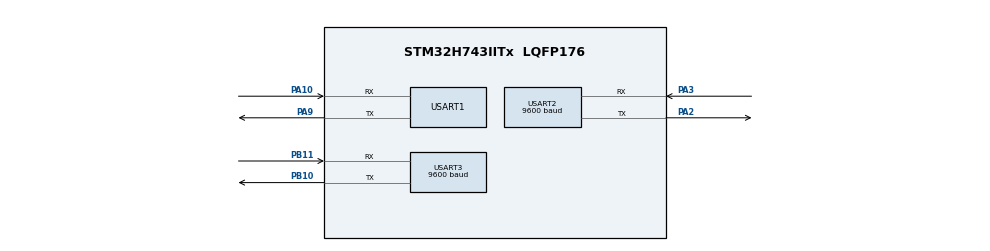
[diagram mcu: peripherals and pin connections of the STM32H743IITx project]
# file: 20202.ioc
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CORTEX_M7.CPU_DCache=Enabled
CORTEX_M7.CPU_ICache=Enabled
CORTEX_M7.default_mode_Activation=1
Mcu.Family=STM32H7
Mcu.Name=STM32H743IITx
Mcu.Package=LQFP176
NVIC.PriorityGroup=NVIC_PRIORITYGROUP_4
PA10.Mode=Asynchronous
PA10.Signal=USART1_RX
PA2.Mode=Asynchronous
PA2.Signal=USART2_TX
PA3.Mode=Asynchronous
PA3.Signal=USART2_RX
PA9.Mode=Asynchronous
PA9.Signal=USART1_TX
PB10.Mode=Asynchronous
PB10.Signal=USART3_TX
PB11.Mode=Asynchronous
PB11.Signal=USART3_RX
PC14-OSC32_IN\ (OSC32_IN).Mode=LSE-External-Oscillator
PC14-OSC32_IN\ (OSC32_IN).Signal=RCC_OSC32_IN
PC15-OSC32_OUT\ (OSC32_OUT).Mode=LSE-External-Oscillator
PC15-OSC32_OUT\ (OSC32_OUT).Signal=RCC_OSC32_OUT
PH0-OSC_IN\ (PH0).Mode=HSE-External-Oscillator
PH0-OSC_IN\ (PH0).Signal=RCC_OSC_IN
PH1-OSC_OUT\ (PH1).Mode=HSE-External-Oscillator
PH1-OSC_OUT\ (PH1).Signal=RCC_OSC_OUT
ProjectManager.HeapSize=0x200
ProjectManager.StackSize=0x400
ProjectManager.TargetToolchain=MDK-ARM V5.32
RCC.ADCFreq_Value=129000000
RCC.APB1Freq_Value=32000000
RCC.APB2Freq_Value=32000000
RCC.APB3Freq_Value=64000000
RCC.APB4Freq_Value=64000000
RCC.CortexFreq_Value=64000000
RCC.D2PPRE1=RCC_APB1_DIV2
RCC.D2PPRE2=RCC_APB2_DIV2
RCC.HCLKFreq_Value=64000000
RCC.SYSCLKFreq_VALUE=64000000
RCC.USBFreq_Value=129000000
USART1.VirtualMode-Asynchronous=VM_ASYNC
USART2.BaudRate=9600
USART2.VirtualMode-Asynchronous=VM_ASYNC
USART3.BaudRate=9600
USART3.VirtualMode-Asynchronous=VM_ASYNC
board=custom

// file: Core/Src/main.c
/* USER CODE BEGIN Header */
/**
 ******************************************************************************
 * @file           : main.c
 * @brief          : Main program body
 ******************************************************************************
 * @attention
 *
 * Copyright (c) 2024 STMicroelectronics.
 * All rights reserved.
 *
 * This software is licensed under terms that can be found in the LICENSE file
 * in the root directory of this software component.
 * If no LICENSE file comes with this software, it is provided AS-IS.
 *
 ******************************************************************************
 */
/* USER CODE END Header */
#include "main.h"
#include "usart.h"
#include "gpio.h"

/* USER CODE BEGIN Includes */
#include "stdio.h"
/* USER CODE END Includes */

/* USER CODE BEGIN PV */
#define FRAME_SIZE 4 // 数据帧长度
/* USER CODE END PV */

void SystemClock_Config(void);
static void MPU_Config(void);
/* USER CODE BEGIN PFP */
uint8_t rxByte;               // 单字节接收缓冲区
uint8_t rxBuffer[FRAME_SIZE]; // 数据帧缓冲区
uint8_t rxIndex = 0;          // 接收索引
uint16_t DistanceValue = 0;   // 距离变量
/* USER CODE END PFP */

int main(void)
{

  /* MPU Configuration--------------------------------------------------------*/
  MPU_Config();

  /* Enable the CPU Cache */

  /* Enable I-Cache---------------------------------------------------------*/
  SCB_EnableICache();

  /* Enable D-Cache---------------------------------------------------------*/
  SCB_EnableDCache();

  /* MCU Configuration--------------------------------------------------------*/

  /* Reset of all peripherals, Initializes the Flash interface and the Systick. */
  HAL_Init();

  /* Configure the system clock */
  SystemClock_Config();

  /* Initialize all configured peripherals */
  MX_GPIO_Init();
  MX_USART1_UART_Init();
  MX_USART2_UART_Init();
  MX_USART3_UART_Init();
  /* USER CODE BEGIN 2 */
  HAL_UART_Receive_IT(&huart2, &rxByte, 1);
  /* USER CODE END 2 */

  /* Infinite loop */
  while (1)
  {
   HAL_UART_RxCpltCallback(&huart2);
  }
}// UART 接收完成回调函数
void HAL_UART_RxCpltCallback(UART_HandleTypeDef *huart)
{
    if (huart->Instance == USART2)
    {
        if (rxBuffer[0] == 0xA5)
        {
            // 校验校验码
            if (rxBuffer[3] == (rxBuffer[0] ^ rxBuffer[1] ^ rxBuffer[2]))
            {
                // 校验数据有效性
                if (rxBuffer[1] == 0xFF && rxBuffer[2] == 0xFF) // 无效数据
                {
                    printf("Invalid data received\n");
                }
                else if (rxBuffer[1] == 0 && rxBuffer[2] == 0) // 距离太近
                {
                    DistanceValue = 0;
                    printf("Distance too close: %d mm\n", DistanceValue);
                }
                else // 正常数据，进行测距
                {
                    DistanceValue = ((uint16_t)rxBuffer[1] << 8) | rxBuffer[2];
                    printf("Distance: %d mm\n", DistanceValue);
                }
            }
            else // 数据错误
            {
                printf("Checksum error\n");
            }
        }
        // 继续接收下一帧数据
        HAL_UART_Receive_IT(&huart2, rxBuffer, FRAME_SIZE);
    }
}
void SystemClock_Config(void)
{
  RCC_OscInitTypeDef RCC_OscInitStruct = {0};
  RCC_ClkInitTypeDef RCC_ClkInitStruct = {0};

  /** Supply configuration update enable
   */
  HAL_PWREx_ConfigSupply(PWR_LDO_SUPPLY);

  /** Configure the main internal regulator output voltage
   */
  __HAL_PWR_VOLTAGESCALING_CONFIG(PWR_REGULATOR_VOLTAGE_SCALE3);

  while (!__HAL_PWR_GET_FLAG(PWR_FLAG_VOSRDY))
  {
  }

  /** Initializes the RCC Oscillators according to the specified parameters
   * in the RCC_OscInitTypeDef structure.
   */
  RCC_OscInitStruct.OscillatorType = RCC_OSCILLATORTYPE_HSI;
  RCC_OscInitStruct.HSIState = RCC_HSI_DIV1;
  RCC_OscInitStruct.HSICalibrationValue = RCC_HSICALIBRATION_DEFAULT;
  RCC_OscInitStruct.PLL.PLLState = RCC_PLL_NONE;
  if (HAL_RCC_OscConfig(&RCC_OscInitStruct) != HAL_OK)
  {
    Error_Handler();
  }

  /** Initializes the CPU, AHB and APB buses clocks
   */
  RCC_ClkInitStruct.ClockType = RCC_CLOCKTYPE_HCLK | RCC_CLOCKTYPE_SYSCLK | RCC_CLOCKTYPE_PCLK1 | RCC_CLOCKTYPE_PCLK2 | RCC_CLOCKTYPE_D3PCLK1 | RCC_CLOCKTYPE_D1PCLK1;
  RCC_ClkInitStruct.SYSCLKSource = RCC_SYSCLKSOURCE_HSI;
  RCC_ClkInitStruct.SYSCLKDivider = RCC_SYSCLK_DIV1;
  RCC_ClkInitStruct.AHBCLKDivider = RCC_HCLK_DIV1;
  RCC_ClkInitStruct.APB3CLKDivider = RCC_APB3_DIV1;
  RCC_ClkInitStruct.APB1CLKDivider = RCC_APB1_DIV2;
  RCC_ClkInitStruct.APB2CLKDivider = RCC_APB2_DIV2;
  RCC_ClkInitStruct.APB4CLKDivider = RCC_APB4_DIV1;

  if (HAL_RCC_ClockConfig(&RCC_ClkInitStruct, FLASH_LATENCY_1) != HAL_OK)
  {
    Error_Handler();
  }
}

/* MPU Configuration */

void MPU_Config(void)
{
  MPU_Region_InitTypeDef MPU_InitStruct = {0};

  /* Disables the MPU */
  HAL_MPU_Disable();

  /** Initializes and configures the Region and the memory to be protected
   */
  MPU_InitStruct.Enable = MPU_REGION_ENABLE;
  MPU_InitStruct.Number = MPU_REGION_NUMBER0;
  MPU_InitStruct.BaseAddress = 0x0;
  MPU_InitStruct.Size = MPU_REGION_SIZE_4GB;
  MPU_InitStruct.SubRegionDisable = 0x87;
  MPU_InitStruct.TypeExtField = MPU_TEX_LEVEL0;
  MPU_InitStruct.AccessPermission = MPU_REGION_NO_ACCESS;
  MPU_InitStruct.DisableExec = MPU_INSTRUCTION_ACCESS_DISABLE;
  MPU_InitStruct.IsShareable = MPU_ACCESS_SHAREABLE;
  MPU_InitStruct.IsCacheable = MPU_ACCESS_NOT_CACHEABLE;
  MPU_InitStruct.IsBufferable = MPU_ACCESS_NOT_BUFFERABLE;

  HAL_MPU_ConfigRegion(&MPU_InitStruct);
  /* Enables the MPU */
  HAL_MPU_Enable(MPU_PRIVILEGED_DEFAULT);
}

void Error_Handler(void)
{
  __disable_irq();
  while (1)
  {
  }
}
